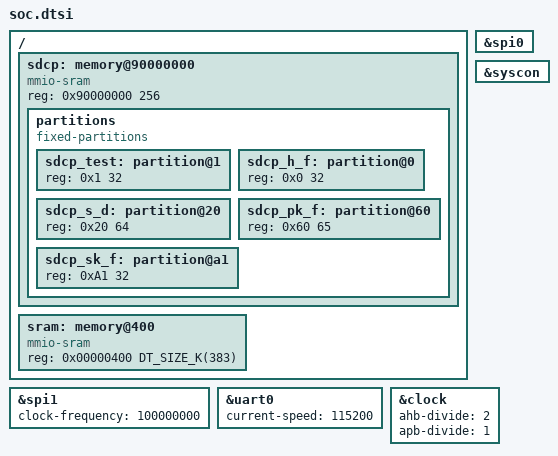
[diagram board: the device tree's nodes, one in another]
/* Copyright 2025 The ChromiumOS Authors.
 * Use of this source code is governed by a BSD-style license that can be
 * found in the LICENSE file.
 */

#include <cros/egis/et171.dtsi>

/delete-node/ &sram;

/ {
	sdcp: memory@90000000 {
		device_type = "memory";
		compatible = "mmio-sram";
		reg = <0x90000000 256>;

		partitions {
			compatible = "fixed-partitions";
			#address-cells = <1>;
			#size-cells = <1>;

			sdcp_test: partition@1 {
				reg = <0x1 32>;
			};
			sdcp_h_f: partition@0 {
				reg = <0x0 32>;
			};
			sdcp_s_d: partition@20 {
				reg = <0x20 64>;
			};
			sdcp_pk_f: partition@60 {
				reg = <0x60 65>;
			};
			sdcp_sk_f: partition@a1 {
				reg = <0xA1 32>;
			};
		};
	};
	sram: memory@400 {
		device_type = "memory";
		compatible = "mmio-sram";
		/* Round down to kB, because the SRAM_SIZE config uses kB as SRAM
		 * size
		 */
		reg = <0x00000400 DT_SIZE_K(383)>;
	};
};

&spi0 {
	status = "okay";
};

&spi1 {
	status = "okay";
	clock-frequency = <100000000>;
};

&syscon {
	status = "okay";
};

&uart0 {
	status = "okay";
	current-speed = <115200>;
	/delete-property/ clock-frequency;
};

&clock {
	ahb-divide = <2>;
	apb-divide = <1>;
};
